# CMS32M67xx register map
Vendor: CMS; Series: CMS32M67xx; File version: 1.2
CPU: CM0+ r0p1, little endian, no MPU, no FPU, VTOR, 2 interrupt priority bits
Registers are 32-bit, read-write, reset 0x0 unless marked. A register's access mark holds for its fields unless they carry their own. Offsets are from the block's base; [hi:lo] are bit positions; {n}, {i} and the like mark numbered series; 'fields as' and 'values as' point back to an identical list.

## CGC — Clock Generate Control
Base 0x40020400
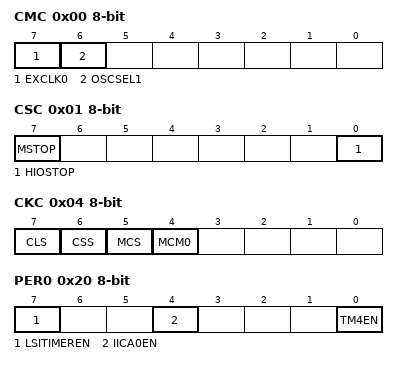
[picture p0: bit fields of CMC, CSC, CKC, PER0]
0x00 CMC 8-bit — Clock operaton Mode Control Register
  [7] EXCLK0 — External Clock input mode
  [6] OSCSEL1 — Main OSC Select
0x01 CSC 8-bit — Clock operation Status Register
  [7] MSTOP — High-speed system clock operation control
    0=START (X1 oscillator operating or External clock from EXCLK pin is valid); 1=STOP (X1 oscillator stop or External clock from EXCLK pin is invalid)
  [0] HIOSTOP — High-speed on-chip oscillator clock operation control
    0=START (High-speed on-chip oscillator operating); 1=STOP (High-speed on-chip oscillator stopped)
0x02 OSTC 8-bit ro — Oscillation stabilization time counter status
0x03 OSTS 8-bit (reset mask 0x7) — Oscillation stabilization time select register
0x04 CKC 8-bit — System clock control register
  [7] CLS ro — Status of CPU/peripheral hardware clock (fCLK)
    0=fMAIN (Main system clock (fMAIN)); 1=fSUB (Subsystem clock (fSUB))
  [6] CSS — Selection of CPU/peripheral hardware clock (fCLK)
    values as CLS
  [5] MCS ro — Status of Main system clock (fMAIN)
    0=fIH (High-speed on-chip oscillator clock (fIH)); 1=fMX (High-speed system clock (fMX))
  [4] MCM0 — Main system clock (fMAIN) operation control
    0=fIH (Select the high-speed on-chip oscillator clock (fIH) as the main system clock (fMAIN)); 1=fMX (Select the high-speed system clock (fMX) as the main system clock (fMAIN))
0x07 SUBCKSEL 8-bit — SubSystem Clock select register
  [0] SELLOCO — Select LOSC or SUBOSC
    0=SUBOSC (Select SUBOSC as the SubSystem clock); 1=LOSC (Select LOSC as the SubSystem clock)
0x08 PMUKEY 16-bit — Power Manager Key Register
0x0A PMUCTL 8-bit — Power Manager Control Register
0x0B RSTM 8-bit — Reset Mask Control Register
{0xC+i} WDTCFG{i} 8-bit (i=0..3) — WDT Configeration {i} register
0x20 PER0 8-bit — Peripheral enable register 0
  [all] fields
    0=Disabled (Disables input clock supply); 1=Enables input clock supply
  [7] LSITIMEREN — Control of the LSITIMER input clock
  [4] IICA0EN — Control of the IICA0 input clock
  [0] TM4EN — Control of the TM4 input clock
0x23 OSMC 8-bit (reset mask 0x88) — Subsystem clock supply mode control register
  [4] WUTMMCK0 — Selection of operation clock for real-time clock, 15-bit interval timer
    0=fSUB (The subsystem clock is selected as the operation clock for the real-time clock and the 15-bit interval timer. The low-speed on-chip oscillator cannot be selected as the count source for timer A.); 1=fIL (The low-speed on-chip oscillator clock is selected as the operation clock for the real-time clock and the 15-bit interval timer. Either the low-speed on-chip oscillator or the subsystem clock can be selected as the count source for timer A.)
0x410 PER10 8-bit — Peripheral enable register 10
  [4] DMAEN — Control of the DMA input clock
    values as the fields of PER0
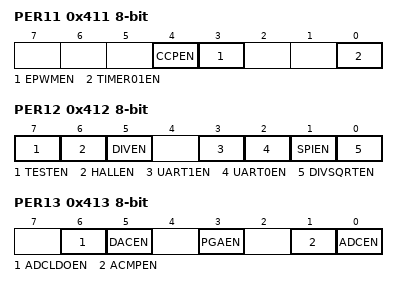
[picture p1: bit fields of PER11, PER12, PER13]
0x411 PER11 8-bit — Peripheral enable register 11
  [all] fields
    values as the fields of PER0
  [4] CCPEN — Control of the CCP input clock
  [3] EPWMEN — Control of the EPWM input clock
  [0] TIMER01EN — Control of the TIMER01 input clock
0x412 PER12 8-bit — Peripheral enable register 12
  [all] fields
    values as the fields of PER0
  [7] TESTEN — Control of the TEST input clock
  [6] HALLEN — Control of the HALL input clock
  [5] DIVEN — Control of the DIV input clock
  [3] UART1EN — Control of the UART1 input clock
  [2] UART0EN — Control of the UART0 input clock
  [1] SPIEN — Control of the SPI input clock
  [0] DIVSQRTEN — Control of the DIVSQRT input clock
0x413 PER13 8-bit — Peripheral enable register 13
  [all] fields
    values as the fields of PER0
  [6] ADCLDOEN — Control of the ADCLDO input clock
  [5] DACEN — Control of the DAC input clock
  [3] PGAEN — Control of the PGA input clock
  [1] ACMPEN — Control of the ACMP input clock
  [0] ADCEN — Control of the ADC input clock
0x800 MCKC (reset mask 0xFF) — frequency select register
0x804 PLLCR (reset mask 0xFF) — PLL frequency select register
0x1800 HIOTRM 8-bit (reset mask 0x3F) — High-speed on-chip oscillator trimming register
0x1820 HOCODIV 8-bit (reset mask 0x7) — High-speed on-chip oscillator frequency select register
